# ATSAMV71Q21 register map
Vendor: Microchip Technology; Series: SAMV71; File version: 0
CPU: CM7 r1p1, little endian, MPU, FPU, 3 interrupt priority bits
Registers are 32-bit, access not given, no defined reset value unless marked. A register's access mark holds for its fields unless they carry their own. Offsets are from the block's base; [hi:lo] are bit positions; {n}, {i} and the like mark numbered series.

## SDRAMC — SDRAM Controller
Base 0x40084000; register names take the prefix SDRAMC_
0x00 SDRAMC_MR — SDRAMC Mode Register
  [2:0] MODE — SDRAMC Command Mode
    0=NORMAL (Normal mode. Any access to the SDRAM is decoded normally. To activate this mode, the command must be followed by a write to the SDRAM.); 1=NOP (The SDRAMC issues a NOP command when the SDRAM device is accessed regardless of the cycle. To activate this mode, the command must be followed by a write to the SDRAM.); 2=ALLBANKS_PRECHARGE (The SDRAMC issues an "All Banks Precharge" command when the SDRAM device is accessed regardless of the cycle. To activate this mode, the command must be followed by a write to the SDRAM.); 3=LOAD_MODEREG (The SDRAMC issues a "Load Mode Register" command when the SDRAM device is accessed regardless of the cycle. To activate this mode, the command must be followed by a write to the SDRAM.); 4=AUTO_REFRESH (The SDRAMC issues an "Auto-Refresh" Command when the SDRAM device is accessed regardless of the cycle. Previously, an "All Banks Precharge" command must be issued. To activate this mode, the command must be followed by a write to the SDRAM.); 5=EXT_LOAD_MODEREG (The SDRAMC issues an "Extended Load Mode Register" command when the SDRAM device is accessed regardless of the cycle. To activate this mode, the "Extended Load Mode Register" command must be followed by a write to the SDRAM. The write in the SDRAM must be done in the appropriate bank; most low-power SDRAM devices use the bank 1.); 6=DEEP_POWERDOWN (Deep Power-down mode. Enters Deep Power-down mode.)
0x04 SDRAMC_TR — SDRAMC Refresh Timer Register
  [11:0] COUNT — SDRAMC Refresh Timer Count
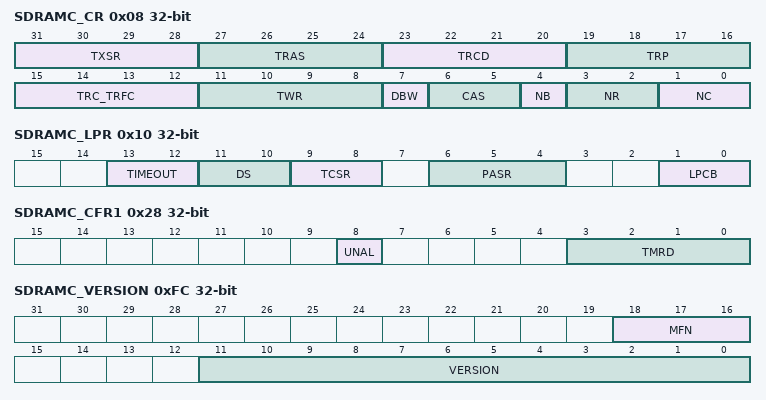
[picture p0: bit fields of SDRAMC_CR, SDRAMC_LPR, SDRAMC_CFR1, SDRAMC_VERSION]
0x08 SDRAMC_CR — SDRAMC Configuration Register
  [31:28] TXSR — Exit Self-Refresh to Active Delay
  [27:24] TRAS — Active to Precharge Delay
  [23:20] TRCD — Row to Column Delay
  [19:16] TRP — Row Precharge Delay
  [15:12] TRC_TRFC — Row Cycle Delay and Row Refresh Cycle
  [11:8] TWR — Write Recovery Delay
  [7] DBW — Data Bus Width
  [6:5] CAS — CAS Latency
    1=LATENCY1 (1 cycle latency); 2=LATENCY2 (2 cycle latency); 3=LATENCY3 (3 cycle latency)
  [4] NB — Number of Banks
    0=BANK2 (2 banks); 1=BANK4 (4 banks)
  [3:2] NR — Number of Row Bits
    0=ROW11 (11 row bits); 1=ROW12 (12 row bits); 2=ROW13 (13 row bits)
  [1:0] NC — Number of Column Bits
    {v}=COL{v+8} ({v+8} column bits) (v=0..3)
0x10 SDRAMC_LPR — SDRAMC Low Power Register
  [13:12] TIMEOUT — Time to Define When Low-power Mode Is Enabled
    0=LP_LAST_XFER (The SDRAMC activates the SDRAM Low-power mode immediately after the end of the last transfer.); 1=LP_LAST_XFER_64 (The SDRAMC activates the SDRAM Low-power mode 64 clock cycles after the end of the last transfer.); 2=LP_LAST_XFER_128 (The SDRAMC activates the SDRAM Low-power mode 128 clock cycles after the end of the last transfer.)
  [11:10] DS — Drive Strength (only for low-power SDRAM)
  [9:8] TCSR — Temperature Compensated Self-Refresh (only for low-power SDRAM)
  [6:4] PASR — Partial Array Self-refresh (only for low-power SDRAM)
  [1:0] LPCB — Low-power Configuration Bits
    0=DISABLED (The low-power feature is inhibited: no Power-down, Self-refresh or Deep Power-down command is issued to the SDRAM device.); 1=SELF_REFRESH (The SDRAMC issues a Self-refresh command to the SDRAM device, the SDCK clock is deactivated and the SDCKE signal is set low. The SDRAM device leaves the Self-refresh mode when accessed and enters it after the access.); 2=POWER_DOWN (The SDRAMC issues a Power-down Command to the SDRAM device after each access, the SDCKE signal is set to low. The SDRAM device leaves the Power-down mode when accessed and enters it after the access.); 3=DEEP_POWER_DOWN (The SDRAMC issues a Deep Power-down command to the SDRAM device. This mode is unique to low-power SDRAM.)
0x14 SDRAMC_IER wo — SDRAMC Interrupt Enable Register
  [0] RES — Refresh Error Interrupt Enable
0x18 SDRAMC_IDR wo — SDRAMC Interrupt Disable Register
  [0] RES — Refresh Error Interrupt Disable
0x1C SDRAMC_IMR ro — SDRAMC Interrupt Mask Register
  [0] RES — Refresh Error Interrupt Mask
0x20 SDRAMC_ISR ro — SDRAMC Interrupt Status Register
  [0] RES — Refresh Error Status (cleared on read)
0x24 SDRAMC_MDR — SDRAMC Memory Device Register
  [1:0] MD — Memory Device Type
    0=SDRAM; 1=LPSDRAM (Low-power SDRAM)
0x28 SDRAMC_CFR1 — SDRAMC Configuration Register 1
  [8] UNAL — Support Unaligned Access
    0=UNSUPPORTED (Unaligned access is not supported.); 1=SUPPORTED (Unaligned access is supported.)
  [3:0] TMRD — Load Mode Register Command to Active or Refresh Command
0x2C SDRAMC_OCMS
  [0] SDR_SE — SDRAM Memory Controller Scrambling Enable
0x30 SDRAMC_OCMS_KEY1 wo
  [31:0] KEY1 — Off-chip Memory Scrambling (OCMS) Key Part 1
0x34 SDRAMC_OCMS_KEY2 wo
  [31:0] KEY2 — Off-chip Memory Scrambling (OCMS) Key Part 2
0xFC SDRAMC_VERSION ro
  [18:16] MFN — Metal Fix Number
  [11:0] VERSION — Version of the Hardware Module
